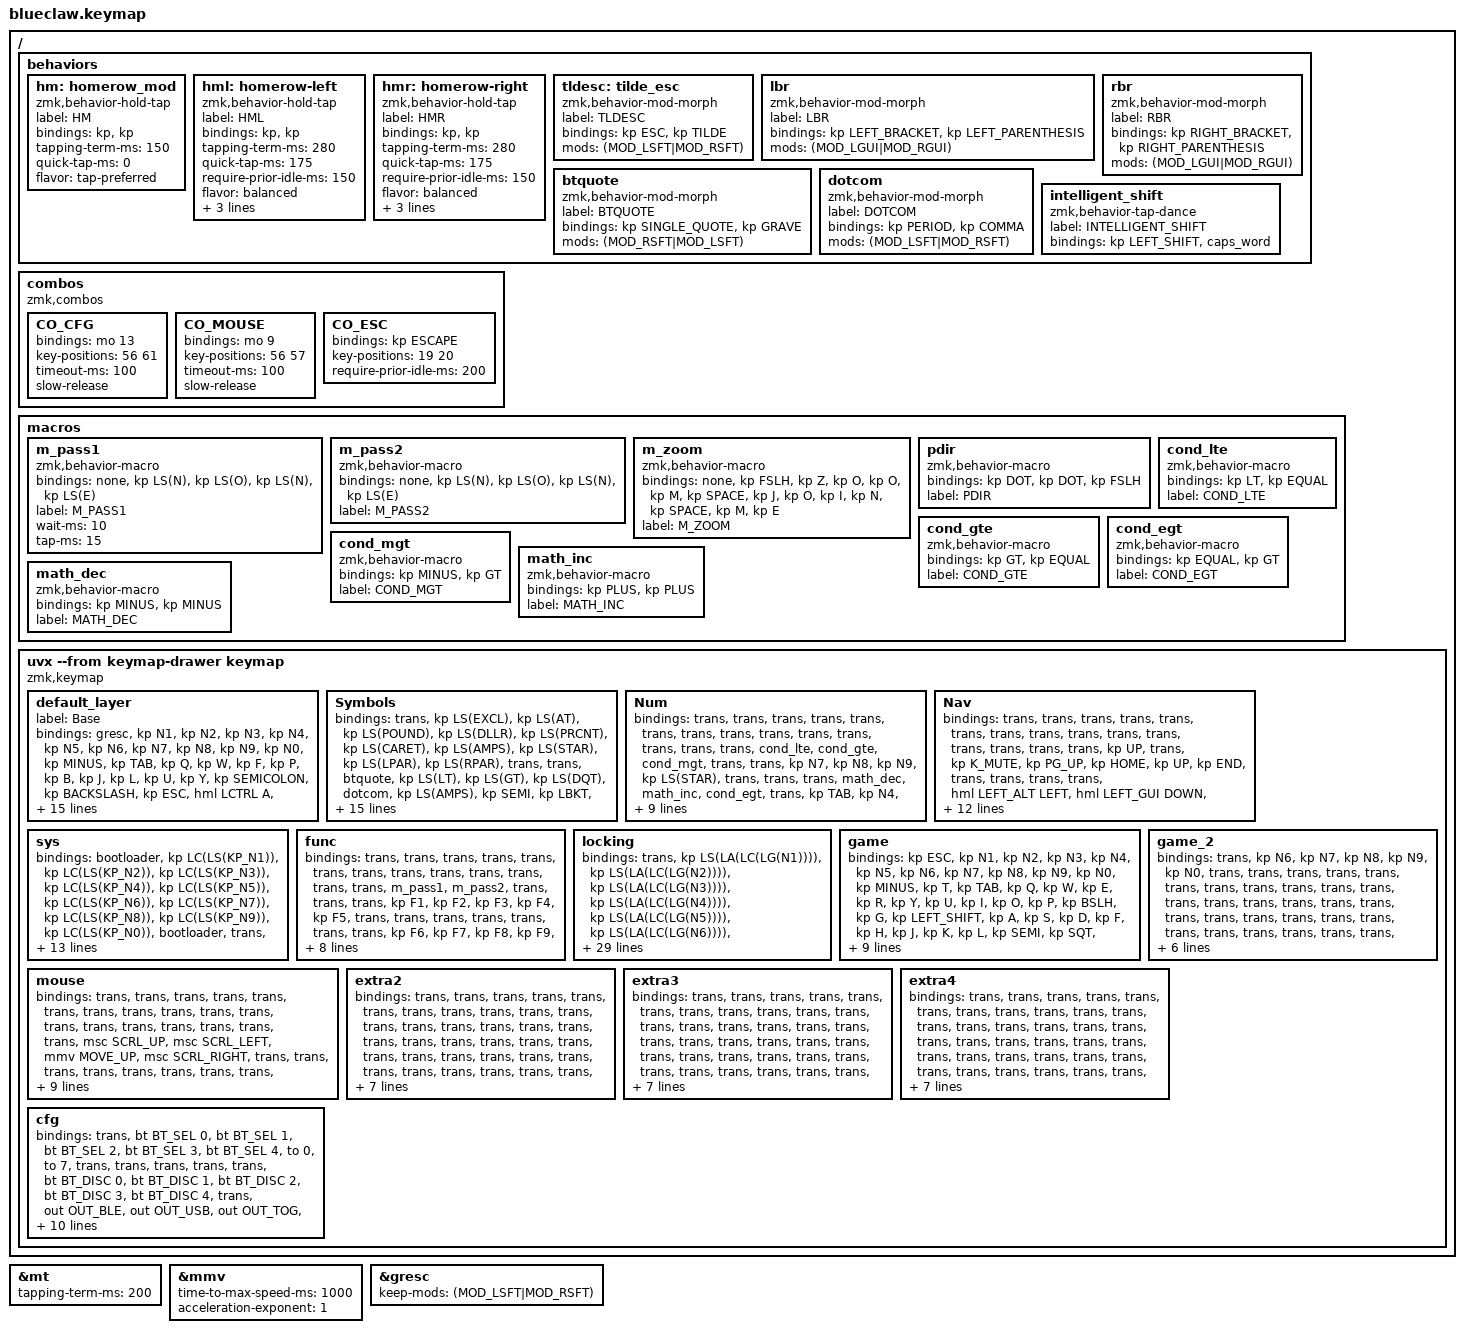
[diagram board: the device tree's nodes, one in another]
/*
 * Copyright (c) 2020 The ZMK Contributors
 *
 * SPDX-License-Identifier: MIT
 */

#include "secrets.dtsi"

#define ZMK_POINTING_DEFAULT_MOVE_VAL 2500  // default: 600
#define ZMK_POINTING_DEFAULT_SCRL_VAL 20    // default: 10

#include <behaviors.dtsi>
#include <dt-bindings/zmk/bt.h>
#include <dt-bindings/zmk/keys.h>
#include <dt-bindings/zmk/outputs.h>
#include <dt-bindings/zmk/pointing.h>

&mt { tapping-term-ms = <200>; };

&mmv {
    time-to-max-speed-ms = <1000>;
    acceleration-exponent = <1>;
};

&gresc { keep-mods = <(MOD_LSFT|MOD_RSFT)>; };

/ {
    behaviors {
        hm: homerow_mod {
            compatible = "zmk,behavior-hold-tap";
            label = "HM";
            bindings = <&kp>, <&kp>;

            #binding-cells = <2>;
            tapping-term-ms = <150>;
            quick-tap-ms = <0>;
            flavor = "tap-preferred";
        };

        hml: homerow-left {
            compatible = "zmk,behavior-hold-tap";
            label = "HML";
            bindings = <&kp>, <&kp>;

            #binding-cells = <2>;
            tapping-term-ms = <280>;
            quick-tap-ms = <175>;
            require-prior-idle-ms = <150>;
            flavor = "balanced";
            hold-trigger-key-positions = <50 51 52 53 54 55 43 44 30 18 6 31 19 7 8 9 10 11 35 22 23 49 48 34 47 57 56 45 46 32 33 21 20 42>;
            hold-trigger-on-release;
        };

        hmr: homerow-right {
            compatible = "zmk,behavior-hold-tap";
            label = "HMR";
            bindings = <&kp>, <&kp>;

            #binding-cells = <2>;
            tapping-term-ms = <280>;
            quick-tap-ms = <175>;
            require-prior-idle-ms = <150>;
            flavor = "balanced";
            hold-trigger-key-positions = <0 1 2 3 4 5 12 13 14 15 16 17 24 25 26 27 28 29 36 37 38 39 40 41 52 53 54 55 56 57 48 49>;
            hold-trigger-on-release;
        };

        tldesc: tilde_esc {
            compatible = "zmk,behavior-mod-morph";
            label = "TLDESC";
            bindings = <&kp ESC>, <&kp TILDE>;

            #binding-cells = <0>;
            mods = <(MOD_LSFT|MOD_RSFT)>;
        };

        lbr: lbr {
            compatible = "zmk,behavior-mod-morph";
            label = "LBR";
            bindings = <&kp LEFT_BRACKET>, <&kp LEFT_PARENTHESIS>;

            #binding-cells = <0>;
            mods = <(MOD_LGUI|MOD_RGUI)>;
        };

        rbr: rbr {
            compatible = "zmk,behavior-mod-morph";
            label = "RBR";
            bindings = <&kp RIGHT_BRACKET>, <&kp RIGHT_PARENTHESIS>;

            #binding-cells = <0>;
            mods = <(MOD_LGUI|MOD_RGUI)>;
        };

        btquote: btquote {
            compatible = "zmk,behavior-mod-morph";
            label = "BTQUOTE";
            bindings = <&kp SINGLE_QUOTE>, <&kp GRAVE>;

            #binding-cells = <0>;
            mods = <(MOD_RSFT|MOD_LSFT)>;
        };

        dotcom: dotcom {
            compatible = "zmk,behavior-mod-morph";
            label = "DOTCOM";
            bindings = <&kp PERIOD>, <&kp COMMA>;

            #binding-cells = <0>;
            mods = <(MOD_LSFT|MOD_RSFT)>;
        };

        intelligent_shift: intelligent_shift {
            compatible = "zmk,behavior-tap-dance";
            label = "INTELLIGENT_SHIFT";
            #binding-cells = <0>;
            bindings = <&kp LEFT_SHIFT>, <&caps_word>;
        };
    };

    combos {
        compatible = "zmk,combos";

        CO_CFG {
            bindings = <&mo 13>;
            key-positions = <56 61>;
            timeout-ms = <100>;
            slow-release;
        };

        CO_MOUSE {
            bindings = <&mo 9>;
            key-positions = <56 57>;
            timeout-ms = <100>;
            slow-release;
        };

        CO_ESC {
            bindings = <&kp ESCAPE>;
            key-positions = <19 20>;
            require-prior-idle-ms = <200>;
        };
    };

    macros {
        m_pass1: m_pass1 {
            compatible = "zmk,behavior-macro";
            #binding-cells = <0>;
            bindings = <&none &kp LS(N) &kp LS(O) &kp LS(N) &kp LS(E)>;
            label = "M_PASS1";
            wait-ms = <10>;
            tap-ms = <15>;
        };

        m_pass2: m_pass2 {
            compatible = "zmk,behavior-macro";
            #binding-cells = <0>;
            bindings = <&none &kp LS(N) &kp LS(O) &kp LS(N) &kp LS(E)>;
            label = "M_PASS2";
        };

        m_zoom: m_zoom {
            compatible = "zmk,behavior-macro";
            #binding-cells = <0>;
            bindings = <&none &kp FSLH &kp Z &kp O &kp O &kp M &kp SPACE &kp J &kp O &kp I &kp N &kp SPACE &kp M &kp E>;
            label = "M_ZOOM";
        };

        pdir: pdir {
            compatible = "zmk,behavior-macro";
            #binding-cells = <0>;
            bindings = <&kp DOT &kp DOT &kp FSLH>;
            label = "PDIR";
        };

        cond_lte: cond_lte {
            compatible = "zmk,behavior-macro";
            #binding-cells = <0>;
            bindings = <&kp LT &kp EQUAL>;
            label = "COND_LTE";
        };

        cond_gte: cond_gte {
            compatible = "zmk,behavior-macro";
            #binding-cells = <0>;
            bindings = <&kp GT &kp EQUAL>;
            label = "COND_GTE";
        };

        cond_egt: cond_egt {
            compatible = "zmk,behavior-macro";
            #binding-cells = <0>;
            bindings = <&kp EQUAL &kp GT>;
            label = "COND_EGT";
        };

        cond_mgt: cond_mgt {
            compatible = "zmk,behavior-macro";
            #binding-cells = <0>;
            bindings = <&kp MINUS &kp GT>;
            label = "COND_MGT";
        };

        math_inc: math_inc {
            compatible = "zmk,behavior-macro";
            #binding-cells = <0>;
            bindings = <&kp PLUS &kp PLUS>;
            label = "MATH_INC";
        };

        math_dec: math_dec {
            compatible = "zmk,behavior-macro";
            #binding-cells = <0>;
            bindings = <&kp MINUS &kp MINUS>;
            label = "MATH_DEC";
        };
    };

    uvx --from keymap-drawer keymap {
        compatible = "zmk,keymap";

        default_layer {
            label = "Base";
            bindings = <
&gresc     &kp N1        &kp N2           &kp N3           &kp N4                &kp N5                                           &kp N6       &kp N7              &kp N8            &kp N9           &kp N0                        &kp MINUS
&kp TAB    &kp Q         &kp W            &kp F            &kp P                 &kp B                                            &kp J        &kp L               &kp U             &kp Y            &kp SEMICOLON                 &kp BACKSLASH
&kp ESC    &hml LCTRL A  &hml LEFT_ALT R  &hml LEFT_GUI S  &hml LEFT_SHIFT T     &kp G                                            &kp M        &hmr RIGHT_SHIFT N  &hmr RIGHT_GUI E  &hmr LEFT_ALT I  &hmr RIGHT_CONTROL O          &kp SQT
&kp LSHFT  &kp Z         &kp X            &kp C            &kp D                 &kp V                                            &kp K        &kp H               &kp COMMA         &kp DOT          &mt LA(LC(LEFT_SHIFT)) SLASH  &kp RSHFT
                         &kp LCTRL        &kp LEFT_ALT                                                                                                             &lbr              &rbr
                                                           &mt LEFT_COMMAND TAB  &lt 3 ENTER  &lt 2 ESCAPE    &intelligent_shift  &lt 1 SPACE  &kp BACKSPACE
                                                                                 &mo 5        &mo 6           &mo 6               &mo 4
           &trans        &kp K_MUTE       &trans
           &trans        &trans           &trans
           &trans        &trans           &trans
            >;

            sensor-bindings = <&inc_dec_kp C_VOLUME_DOWN C_VOLUME_UP>;
        };

        Symbols {
            bindings = <
&trans  &kp LS(EXCL)            &kp LS(AT)           &kp LS(POUND)       &kp LS(DLLR)           &kp LS(PRCNT)                    &kp LS(CARET)  &kp LS(AMPS)           &kp LS(STAR)                    &kp LS(LPAR)                     &kp LS(RPAR)         &trans
&trans  &btquote                &kp LS(LT)           &kp LS(GT)          &kp LS(DQT)            &dotcom                          &kp LS(AMPS)   &kp SEMI               &kp LBKT                        &kp RBKT                         &kp LS(PRCNT)        &trans
&trans  &hml LCTRL EXCLAMATION  &hml LEFT_ALT MINUS  &hml LEFT_GUI PLUS  &hml LEFT_SHIFT EQUAL  &kp HASH                         &kp LS(PIPE)   &hmr LEFT_SHIFT COLON  &hmr LEFT_GUI LEFT_PARENTHESIS  &hmr LEFT_ALT RIGHT_PARENTHESIS  &hmr RCTRL QUESTION  &trans
&trans  &kp LS(CARET)           &kp FSLH             &kp LS(STAR)        &kp BSLH               &pdir                            &kp LS(TILDE)  &kp LS(DLLR)           &kp LS(LBRC)                    &kp LS(RBRC)                     &kp LS(AT)           &trans
                                &trans               &trans                                                                                                            &trans                          &trans
                                                                         &trans                 &trans         &trans    &trans  &trans         &kp DELETE
                                                                                                &trans         &trans    &tog 1  &trans
        &trans                  &trans               &trans
        &trans                  &trans               &trans
        &trans                  &trans               &trans
            >;

            label = "symbols";
        };

        Num {
            bindings = <
&trans  &trans  &trans     &trans     &trans     &trans                        &trans   &trans  &trans     &trans      &trans        &trans
&trans  &trans  &cond_lte  &cond_gte  &cond_mgt  &trans                        &trans   &kp N7  &kp N8     &kp N9      &kp LS(STAR)  &trans
&trans  &trans  &math_dec  &math_inc  &cond_egt  &trans                        &kp TAB  &kp N4  &kp N5     &kp N6      &kp LS(PLUS)  &kp MINUS
&trans  &trans  &trans     &trans     &trans     &trans                        &kp N0   &kp N1  &kp N2     &kp N3      &kp BSLH      &kp EQUAL
                &trans     &trans                                                               &kp COMMA  &kp PERIOD
                                      &trans     &trans  &trans    &caps_word  &trans   &trans
                                                 &trans  &tog 2    &trans      &trans
        &trans  &trans     &trans
        &trans  &trans     &trans
        &trans  &trans     &trans
            >;

            label = "numbers";
        };

        Nav {
            bindings = <
&trans  &trans  &trans              &trans              &trans                 &trans                                  &trans      &trans           &trans            &trans      &trans             &trans
&trans  &trans  &trans              &kp UP              &trans                 &kp K_MUTE                              &kp PG_UP   &kp HOME         &kp UP            &kp END     &trans             &trans
&trans  &trans  &hml LEFT_ALT LEFT  &hml LEFT_GUI DOWN  &hml LEFT_SHIFT RIGHT  &kp C_VOLUME_UP                         &kp PG_DN   &kp LEFT         &kp DOWN          &kp RIGHT   &kp K_APPLICATION  &kp ENTER
&trans  &trans  &trans              &kp K_COPY          &kp K_PASTE            &kp C_VOL_DN                            &kp C_STOP  &kp C_PREV       &kp C_PLAY_PAUSE  &kp C_NEXT  &trans             &trans
                &trans              &trans                                                                                                          &trans            &trans
                                                        &trans                 &trans           &trans    &kp DELETE   &mo 9       &lt 9 BACKSPACE
                                                                               &trans           &tog 3    &key_repeat  &trans
        &trans  &trans              &trans
        &trans  &trans              &trans
        &trans  &trans              &trans
            >;

            label = "Nav";
        };

        sys {
            bindings = <
&bootloader   &kp LC(LS(KP_N1))  &kp LC(LS(KP_N2))  &kp LC(LS(KP_N3))  &kp LC(LS(KP_N4))  &kp LC(LS(KP_N5))                    &kp LC(LS(KP_N6))  &kp LC(LS(KP_N7))  &kp LC(LS(KP_N8))  &kp LC(LS(KP_N9))  &kp LC(LS(KP_N0))  &bootloader
&trans        &m_pass1           &m_pass2           &trans             &trans             &trans                               &kp LC(LS(KP_N1))  &kp LC(LS(KP_N2))  &kp UP             &trans             &trans             &trans
&kp CAPSLOCK  &caps_word         &trans             &trans             &trans             &to 7                                &trans             &kp LEFT           &kp DOWN           &kp RIGHT          &trans             &trans
&trans        &m_zoom            &trans             &trans             &trans             &to 0                                &kp K_LOCK         &trans             &trans             &trans             &trans             &trans
                                 &trans             &trans                                                                                                           &trans             &trans
                                                                       &trans             &trans             &trans    &trans  &trans             &kp DELETE
                                                                                          &trans             &trans    &tog 4  &trans
              &bootloader        &trans             &trans
              &trans             &trans             &trans
              &trans             &trans             &studio_unlock
            >;

            label = "sys";
        };

        func {
            bindings = <
&trans  &trans    &trans    &trans  &trans  &trans                    &trans   &trans   &trans   &trans   &trans   &trans
&trans  &m_pass1  &m_pass2  &trans  &trans  &trans                    &kp F1   &kp F2   &kp F3   &kp F4   &kp F5   &trans
&trans  &trans    &trans    &trans  &trans  &trans                    &kp F6   &kp F7   &kp F8   &kp F9   &kp F10  &trans
&trans  &trans    &trans    &trans  &trans  &trans                    &kp F11  &kp F12  &kp F13  &kp F14  &kp F15  &trans
                  &trans    &trans                                                      &trans   &trans
                                    &trans  &trans  &trans    &trans  &trans   &trans
                                            &trans  &tog 5    &trans  &trans
        &trans    &trans    &trans
        &trans    &trans    &trans
        &trans    &trans    &trans
            >;

            label = "f-keys";
        };

        locking {
            bindings = <
&trans  &kp LS(LA(LC(LG(N1))))  &kp LS(LA(LC(LG(N2))))  &kp LS(LA(LC(LG(N3))))  &kp LS(LA(LC(LG(N4))))  &kp LS(LA(LC(LG(N5))))                    &kp LS(LA(LC(LG(N6))))  &kp LS(LA(LC(LG(N7))))  &kp LS(LA(LC(LG(N8))))     &kp LS(LA(LC(LG(N9))))   &kp LS(LA(LC(LG(N0))))         &kp LS(LA(LC(LG(MINUS))))
&trans  &kp LS(LA(LC(LG(Q))))   &kp LS(LA(LC(LG(W))))   &kp LS(LA(LC(LG(F))))   &kp LS(LA(LC(LG(P))))   &kp LS(LA(LC(LG(B))))                     &kp LS(LA(LC(LG(J))))   &kp LS(LA(LC(LG(L))))   &kp LS(LA(LC(LG(U))))      &kp LS(LA(LC(LG(Y))))    &kp LS(LA(LC(LG(SEMICOLON))))  &kp LS(LA(LC(LG(BACKSLASH))))
&trans  &kp LS(LA(LC(LG(A))))   &kp LS(LA(LC(LG(R))))   &kp LS(LA(LC(LG(S))))   &kp LS(LA(LC(LG(T))))   &kp LS(LA(LC(LG(G))))                     &kp LS(LA(LC(LG(M))))   &kp LS(LA(LC(LG(N))))   &kp LS(LA(LC(LG(E))))      &kp LS(LA(LC(LG(I))))    &kp LS(LA(LC(LG(O))))          &kp LS(LA(LC(LG(SQT))))
&trans  &kp LS(LA(LC(LG(Z))))   &kp LS(LA(LC(LG(X))))   &kp LS(LA(LC(LG(C))))   &kp LS(LA(LC(LG(D))))   &kp LS(LA(LC(LG(V))))                     &kp LS(LA(LC(LG(K))))   &kp LS(LA(LC(LG(H))))   &kp LS(LA(LC(LG(COMMA))))  &kp LS(LA(LC(LG(DOT))))  &trans                         &trans
                                &trans                  &trans                                                                                                                                    &trans                     &trans
                                                                                &trans                  &to 3                   &to 2     &trans  &to 1                   &trans
                                                                                                        &to 5                   &trans    &trans  &to 4
        &trans                  &trans                  &trans
        &trans                  &trans                  &trans
        &trans                  &trans                  &trans
            >;

            label = "layers";
        };

        game {
            bindings = <
&kp ESC  &kp N1          &kp N2    &kp N3    &kp N4      &kp N5                                 &kp N6     &kp N7  &kp N8     &kp N9    &kp N0    &kp MINUS
&kp T    &kp TAB         &kp Q     &kp W     &kp E       &kp R                                  &kp Y      &kp U   &kp I      &kp O     &kp P     &kp BSLH
&kp G    &kp LEFT_SHIFT  &kp A     &kp S     &kp D       &kp F                                  &kp H      &kp J   &kp K      &kp L     &kp SEMI  &kp SQT
&kp V    &kp LCTRL       &kp Z     &kp X     &kp C       &kp B                                  &kp N      &kp M   &kp COMMA  &kp DOT   &kp FSLH  &kp RSHFT
                         &kp LBKT  &kp RBKT                                                                        &kp RGUI   &kp LALT
                                             &lt 8 LALT  &kp SPACE  &kp ENTER      &kp ENTER    &kp SPACE  &trans
                                                         &kp LCTRL  &key_repeat    &key_repeat  &mo 4
         &trans          &trans    &trans
         &trans          &trans    &trans
         &trans          &trans    &trans
            >;

            label = "game";
        };

        game_2 {
            bindings = <
&trans  &kp N6  &kp N7  &kp N8  &kp N9  &kp N0                    &trans  &trans  &trans  &trans  &trans  &trans
&trans  &trans  &trans  &trans  &trans  &trans                    &trans  &trans  &trans  &trans  &trans  &trans
&trans  &trans  &trans  &trans  &trans  &trans                    &trans  &trans  &trans  &trans  &trans  &trans
&trans  &trans  &trans  &trans  &trans  &trans                    &trans  &trans  &trans  &trans  &trans  &trans
                &trans  &trans                                                    &trans  &trans
                                &trans  &trans  &trans    &trans  &trans  &trans
                                        &trans  &trans    &trans  &trans
        &trans  &trans  &trans
        &trans  &trans  &trans
        &trans  &trans  &trans
            >;
        };

        mouse {
            bindings = <
&trans  &trans  &trans  &trans  &trans  &trans                    &trans          &trans          &trans          &trans           &trans  &trans
&trans  &trans  &trans  &trans  &trans  &trans                    &msc SCRL_UP    &msc SCRL_LEFT  &mmv MOVE_UP    &msc SCRL_RIGHT  &trans  &trans
&trans  &trans  &trans  &trans  &trans  &trans                    &msc SCRL_DOWN  &mmv MOVE_LEFT  &mmv MOVE_DOWN  &mmv MOVE_RIGHT  &trans  &trans
&trans  &trans  &trans  &trans  &trans  &trans                    &trans          &mkp LCLK       &mkp MCLK       &mkp RCLK        &trans  &trans
                &trans  &trans                                                                    &trans          &trans
                                &trans  &trans  &trans    &trans  &trans          &trans
                                        &trans  &trans    &trans  &trans
        &trans  &trans  &trans
        &trans  &trans  &trans
        &trans  &trans  &trans
            >;

            label = "mouse";
        };

        extra2 {
            bindings = <
&trans  &trans  &trans  &trans  &trans  &trans                    &trans  &trans  &trans  &trans  &trans  &trans
&trans  &trans  &trans  &trans  &trans  &trans                    &trans  &trans  &trans  &trans  &trans  &trans
&trans  &trans  &trans  &trans  &trans  &trans                    &trans  &trans  &trans  &trans  &trans  &trans
&trans  &trans  &trans  &trans  &trans  &trans                    &trans  &trans  &trans  &trans  &trans  &trans
                &trans  &trans                                                    &trans  &trans
                                &trans  &trans  &trans    &trans  &trans  &trans
                                        &trans  &trans    &trans  &trans
        &trans  &trans  &trans
        &trans  &trans  &trans
        &trans  &trans  &trans
            >;

            label = "extra2";
        };

        extra3 {
            bindings = <
&trans  &trans  &trans  &trans  &trans  &trans                    &trans  &trans  &trans  &trans  &trans  &trans
&trans  &trans  &trans  &trans  &trans  &trans                    &trans  &trans  &trans  &trans  &trans  &trans
&trans  &trans  &trans  &trans  &trans  &trans                    &trans  &trans  &trans  &trans  &trans  &trans
&trans  &trans  &trans  &trans  &trans  &trans                    &trans  &trans  &trans  &trans  &trans  &trans
                &trans  &trans                                                    &trans  &trans
                                &trans  &trans  &trans    &trans  &trans  &trans
                                        &trans  &trans    &trans  &trans
        &trans  &trans  &trans
        &trans  &trans  &trans
        &trans  &trans  &trans
            >;

            label = "extra3";
        };

        extra4 {
            bindings = <
&trans  &trans  &trans  &trans  &trans  &trans                    &trans  &trans  &trans  &trans  &trans  &trans
&trans  &trans  &trans  &trans  &trans  &trans                    &trans  &trans  &trans  &trans  &trans  &trans
&trans  &trans  &trans  &trans  &trans  &trans                    &trans  &trans  &trans  &trans  &trans  &trans
&trans  &trans  &trans  &trans  &trans  &trans                    &trans  &trans  &trans  &trans  &trans  &trans
                &trans  &trans                                                    &trans  &trans
                                &trans  &trans  &trans    &trans  &trans  &trans
                                        &trans  &trans    &trans  &trans
        &trans  &trans  &trans
        &trans  &trans  &trans
        &trans  &trans  &trans
            >;

            label = "extra4";
        };

        cfg {
            bindings = <
&trans  &bt BT_SEL 0   &bt BT_SEL 1   &bt BT_SEL 2   &bt BT_SEL 3   &bt BT_SEL 4                     &to 0   &to 7         &trans        &trans        &trans  &trans
&trans  &bt BT_DISC 0  &bt BT_DISC 1  &bt BT_DISC 2  &bt BT_DISC 3  &bt BT_DISC 4                    &trans  &out OUT_BLE  &out OUT_USB  &out OUT_TOG  &trans  &trans
&trans  &trans         &trans         &trans         &trans         &trans                           &trans  &trans        &trans        &trans        &trans  &trans
&trans  &trans         &bt BT_CLR     &trans         &trans         &trans                           &trans  &trans        &trans        &trans        &trans  &trans
                       &trans         &trans                                                                               &trans        &trans
                                                     &trans         &trans         &trans    &trans  &trans  &trans
                                                                    &trans         &trans    &trans  &trans
        &trans         &trans         &trans
        &trans         &trans         &trans
        &trans         &trans         &trans
            >;

            label = "BIOS";
        };
    };
};

// THIS WILL Be a defined makro when compiled with secrets, or empty when no secrets are in play

INJECT_SECRETS()
